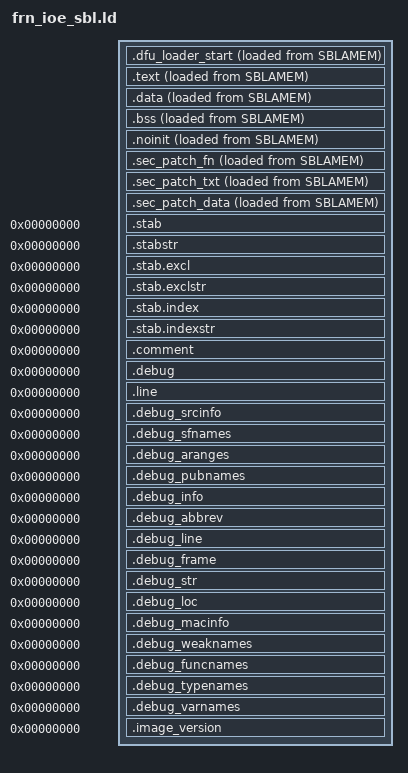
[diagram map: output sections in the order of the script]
/*
* Copyright (c) 2024 Qualcomm Innovation Center, Inc. All rights reserved.
* SPDX-License-Identifier: BSD-3-Clause-Clear
*/

/*
 * Memory Spaces Definitions.
 */


INCLUDE frn_ioe_bl_cmn.ld

/*Neutrino OTP region address start*/
 __OTP_region_st_addr = ORIGIN(OTPMEM);
 __OTP_region_end_addr = ORIGIN(OTPMEM) + LENGTH(OTPMEM);
 __OTP_rfregion_st_addr = ORIGIN(OTPRFMEM);
 __OTP_rfregion_end_addr = ORIGIN(OTPRFMEM) + LENGTH(OTPRFMEM);

 /*RRAM main memory address space*/
 __rram_region_start_addr = ORIGIN(PBLMEM);
 __rram_region_end_address = ORIGIN(PBLMEM) + LENGTH(PBLMEM) + LENGTH(PBL_PATCH) +LENGTH(FDTMEM) + LENGTH(SBLAMEM) + LENGTH(SBLBMEM) + LENGTH(RRAMMEM);

  /*FDT address space*/
 __fdt_reg_st_addr = ORIGIN(FDTMEM);
 __fdt_reg_end_addr = ORIGIN(FDTMEM) + LENGTH(FDTMEM);

/*PBL patch function start address*/
 __sec_patch_start = ORIGIN(PBL_PATCH);

 /* config table in ram */
 __config_table = ORIGIN(CONFIG_TABLE);
 __config_table_size = LENGTH(CONFIG_TABLE);

__app_image_start_addr = ORIGIN(RRAMMEM);
__app_image_xip_start_addr = ORIGIN(FLASH_XIP);
__raw_file_start_addr = ORIGIN(UDPARTMEM);
/*
 * The entry point for SBL, which is used to load first function of SBL
 */
ENTRY(loader_start)


/* Sections Definitions */

SECTIONS
{
	.dfu_loader_start : ALIGN(4)
	{
		/*
		* This section is here for convenience, to store the
		* startup code at the beginning of the flash area, hoping that
		* this will increase the readability of the listing.
		*/
		KEEP (*(.dfu_loader_start)) /* Boot code and ISR */

		. = ALIGN(4);

	} >SBL_RAM_RO AT> SBLAMEM

	/*
	* The program code is stored in the .text section,
	* which goes to FLASH.
	*/
	.text : ALIGN(4)
	{
		EXCLUDE_FILE(*pbl_patch.o)
		*(.text .text.*) /* all remaining code */
		EXCLUDE_FILE(*pbl_patch.o)
		*(.rodata .rodata.* .constdata .constdata.*) /* read-only data (constants) */
		*(vtable) /* C++ virtual tables */

		KEEP(*(.eh_frame*))

		/*
		* Stub sections generated by the linker, to glue together
		* ARM and Thumb code. .glue_7 is used for ARM code calling
		* Thumb code, and .glue_7t is used for Thumb code calling
		* ARM code. Apparently always generated by the linker, for some
		* architectures, so better leave them here.
		*/
		*(.glue_7)
		*(.glue_7t)

	} >SBL_RAM_RO AT> SBLAMEM

	/*
	* The initialised data section.
	*
	* The program executes knowing that the data is in the RAM
	* but the loader puts the initial values in the FLASH (inidata).
	* It is one task of the startup to copy the initial values from
	* FLASH to RAM.
	*/
	.data : ALIGN(4)
	{
		FILL(0xFF)

		/* This is used by the startup code to initialise the .data section */

		_ln__data_start__ = . ;
		EXCLUDE_FILE(*pbl_patch.o)
		*(.data_begin .data_begin.*)
		EXCLUDE_FILE(*pbl_patch.o)
		*(.data .data.*)
		EXCLUDE_FILE(*pbl_patch.o)
		*(.data_end .data_end.*)
		. = ALIGN(4);

		/* This is used by the startup code to initialise the .data section */

		_ln__data_end__ = . ;

	} >SBL_RAM_RW AT> SBLAMEM
	_ln_RF_start_addr_data__ = LOADADDR(.data);
	_ln__data_size__ = SIZEOF(.data) ;

	/*
	* The uninitialised data sections. NOLOAD is used to avoid
	* the "section `.bss' type changed to PROGBITS" warning
	*/

	/* The primary uninitialised data section. */
	.bss (NOLOAD) : ALIGN(4)
	{
		_ln__bss_start__ = .;     /* standard newlib definition */
		*(.bss_begin .bss_begin.*)

		*(.bss .bss.*)
		*(COMMON)

		*(.bss_end .bss_end.*)
		. = ALIGN(4);
		_ln__bss_end__ = .;        /* standard newlib definition */
	} >SBL_RAM_RW AT> SBLAMEM
	_ln__bss_size__ = SIZEOF(.bss);

	.noinit (NOLOAD) : ALIGN(4)
	{
		_noinit = .;

		*(.noinit .noinit.*)

		. = ALIGN(4) ;
		_end_noinit = .;  
	} >SBL_RAM_RW AT> SBLAMEM


	/* Mandatory to be word aligned, _sbrk assumes this */
	PROVIDE ( end = _end_noinit ); /* was _ebss */
	PROVIDE ( _end = _end_noinit );
	PROVIDE ( __end = _end_noinit );
	PROVIDE ( __end__ = _end_noinit );

	.sec_patch_fn : ALIGN(16)
	{
		/* This section is for PBL patcher functions. This is placed at the
		 * starting of PBL_PATCH MEMORY for convenience.
		 */
		KEEP (*(.pbl_patch_fn))

		/* 4 byte status flag with magic number 0xC0C0CAFE to indicate patch
		* availability. To be update from FDT after patch validation.
		*/
		LONG (0xC0C0CAFE)
		KEEP (*(.pbl_version_num))

		. = ALIGN(16);
	} >PBL_PATCH_RO AT> SBLAMEM 

	.sec_patch_txt : ALIGN(16)
	{
        /*pbl_patch text and read-only data*/
		*pbl_patch.o(.text .text.*)
		*pbl_patch.o(.rodata .rodata.* .constdata .constdata.*)

		. = ALIGN(16);
	} >PBL_PATCH_RO AT> SBLAMEM 

	.sec_patch_data : ALIGN(16)
	{
        /*pbl_patch .data*/
		*pbl_patch.o(.data .data.*)

		. = ALIGN(16);
	} >PBL_PATCH_RW AT> SBLAMEM

	_ln_RF_start_addr_patch_data__ = LOADADDR(.sec_patch_data);
	_ln_RAM_start_addr_patch_data__ = ADDR(.sec_patch_data);
	_ln_patch_data_size__ = SIZEOF(.sec_patch_data);

	/* After that there are only debugging sections. */

	/* This can remove the debugging information from the standard libraries */


	/* Stabs debugging sections.  */
	.stab          0 : { *(.stab) }
	.stabstr       0 : { *(.stabstr) }
	.stab.excl     0 : { *(.stab.excl) }
	.stab.exclstr  0 : { *(.stab.exclstr) }
	.stab.index    0 : { *(.stab.index) }
	.stab.indexstr 0 : { *(.stab.indexstr) }
	.comment       0 : { *(.comment) }
	/*
	* DWARF debug sections.
	* Symbols in the DWARF debugging sections are relative to the beginning
	* of the section so we begin them at 0.
	*/
	/* DWARF 1 */
	.debug          0 : { *(.debug) }
	.line           0 : { *(.line) }
	/* GNU DWARF 1 extensions */
	.debug_srcinfo  0 : { *(.debug_srcinfo) }
	.debug_sfnames  0 : { *(.debug_sfnames) }
	/* DWARF 1.1 and DWARF 2 */
	.debug_aranges  0 : { *(.debug_aranges) }
	.debug_pubnames 0 : { *(.debug_pubnames) }
	/* DWARF 2 */
	.debug_info     0 : { *(.debug_info .gnu.linkonce.wi.*) }
	.debug_abbrev   0 : { *(.debug_abbrev) }
	.debug_line     0 : { *(.debug_line) }
	.debug_frame    0 : { *(.debug_frame) }
	.debug_str      0 : { *(.debug_str) }
	.debug_loc      0 : { *(.debug_loc) }
	.debug_macinfo  0 : { *(.debug_macinfo) }
	/* SGI/MIPS DWARF 2 extensions */
	.debug_weaknames 0 : { *(.debug_weaknames) }
	.debug_funcnames 0 : { *(.debug_funcnames) }
	.debug_typenames 0 : { *(.debug_typenames) }
	.debug_varnames  0 : { *(.debug_varnames) }
	.image_version 0 (INFO): { KEEP(*(.sbl_version_num)) }
}
